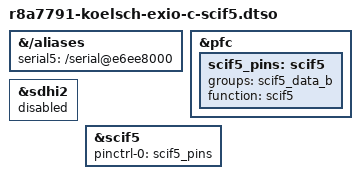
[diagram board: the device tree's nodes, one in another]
/*
 * Device Tree Overlay for SCIF5 on r8a7791/Koelsch EXIO Connector C
 *
 * Copyright (C) 2015 Glider bvba
 *
 * This file is licensed under the terms of the GNU General Public License
 * version 2.  This program is licensed "as is" without any warranty of any
 * kind, whether express or implied.
 *
 * Pinout:
 *   - TXD = EXIO Connector C pin 37
 *   - RXD = EXIO Connector C pin 39
 *
 * Notes:
 *   - As these pins are shared with SDHI2, the latter is disabled first.
 */

/dts-v1/;
/plugin/;

/ {
	fragment-aliases {
		target-path = "/aliases";

		__overlay__ {
			/* serial5 = &scif5; */
			serial5 = "/serial@e6ee8000";
		};
	};

	fragment-pfc {
		target = <&pfc>;

		__overlay__ {
			scif5_pins: scif5 {
				groups = "scif5_data_b";
				function = "scif5";
			};
		};
	};

	fragment-sdhi2 {
		target = <&sdhi2>;

		__overlay__ {
			status = "disabled";
		};
	};

	fragment-scif5 {
		target = <&scif5>;

		__overlay__ {
			pinctrl-0 = <&scif5_pins>;
			pinctrl-names = "default";

			status = "okay";
		};
	};
};
